# ipro6s register map
Vendor: intelpro; Series: IPRO6S
CPU: ipro6s, little endian
Registers are 32-bit, read-write, reset 0x0 unless marked. A register's access mark holds for its fields unless they carry their own. Offsets are from the block's base; [hi:lo] are bit positions; {n}, {i} and the like mark numbered series.

## RF (part 2 of 2)
Base 0x30001000
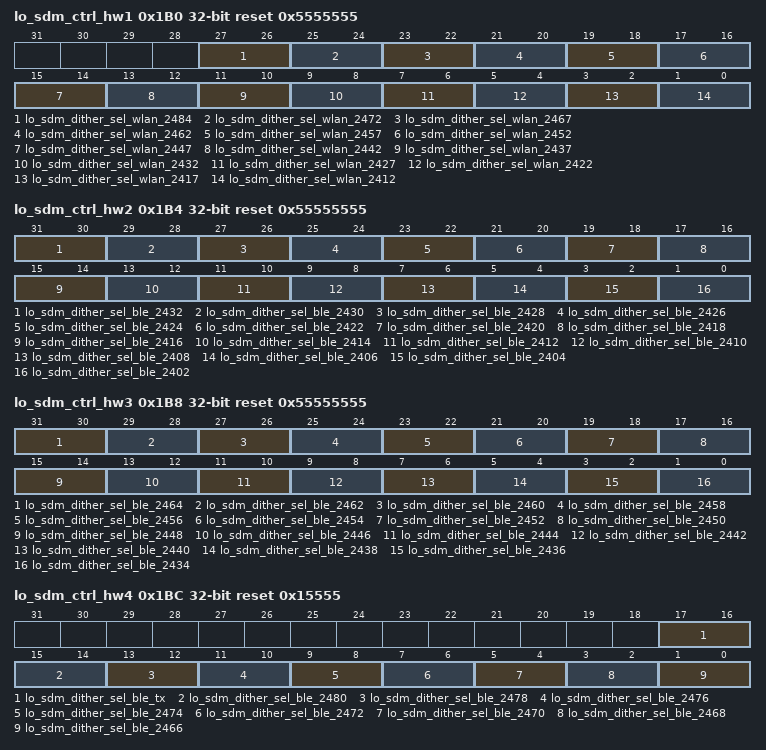
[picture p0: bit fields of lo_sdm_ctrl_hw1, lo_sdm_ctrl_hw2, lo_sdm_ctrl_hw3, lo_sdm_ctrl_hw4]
0x1B0 lo_sdm_ctrl_hw1 reset 0x5555555
  [27:26] lo_sdm_dither_sel_wlan_2484, [25:24] lo_sdm_dither_sel_wlan_2472, [23:22] lo_sdm_dither_sel_wlan_2467, [21:20] lo_sdm_dither_sel_wlan_2462, [19:18] lo_sdm_dither_sel_wlan_2457, [17:16] lo_sdm_dither_sel_wlan_2452, [15:14] lo_sdm_dither_sel_wlan_2447, [13:12] lo_sdm_dither_sel_wlan_2442, [11:10] lo_sdm_dither_sel_wlan_2437, [9:8] lo_sdm_dither_sel_wlan_2432, [7:6] lo_sdm_dither_sel_wlan_2427, [5:4] lo_sdm_dither_sel_wlan_2422, [3:2] lo_sdm_dither_sel_wlan_2417, [1:0] lo_sdm_dither_sel_wlan_2412
0x1B4 lo_sdm_ctrl_hw2 reset 0x55555555
  [31:30] lo_sdm_dither_sel_ble_2432, [29:28] lo_sdm_dither_sel_ble_2430, [27:26] lo_sdm_dither_sel_ble_2428, [25:24] lo_sdm_dither_sel_ble_2426, [23:22] lo_sdm_dither_sel_ble_2424, [21:20] lo_sdm_dither_sel_ble_2422, [19:18] lo_sdm_dither_sel_ble_2420, [17:16] lo_sdm_dither_sel_ble_2418, [15:14] lo_sdm_dither_sel_ble_2416, [13:12] lo_sdm_dither_sel_ble_2414, [11:10] lo_sdm_dither_sel_ble_2412, [9:8] lo_sdm_dither_sel_ble_2410, [7:6] lo_sdm_dither_sel_ble_2408, [5:4] lo_sdm_dither_sel_ble_2406, [3:2] lo_sdm_dither_sel_ble_2404, [1:0] lo_sdm_dither_sel_ble_2402
0x1B8 lo_sdm_ctrl_hw3 reset 0x55555555
  [31:30] lo_sdm_dither_sel_ble_2464, [29:28] lo_sdm_dither_sel_ble_2462, [27:26] lo_sdm_dither_sel_ble_2460, [25:24] lo_sdm_dither_sel_ble_2458, [23:22] lo_sdm_dither_sel_ble_2456, [21:20] lo_sdm_dither_sel_ble_2454, [19:18] lo_sdm_dither_sel_ble_2452, [17:16] lo_sdm_dither_sel_ble_2450, [15:14] lo_sdm_dither_sel_ble_2448, [13:12] lo_sdm_dither_sel_ble_2446, [11:10] lo_sdm_dither_sel_ble_2444, [9:8] lo_sdm_dither_sel_ble_2442, [7:6] lo_sdm_dither_sel_ble_2440, [5:4] lo_sdm_dither_sel_ble_2438, [3:2] lo_sdm_dither_sel_ble_2436, [1:0] lo_sdm_dither_sel_ble_2434
0x1BC lo_sdm_ctrl_hw4 reset 0x15555
  [17:16] lo_sdm_dither_sel_ble_tx, [15:14] lo_sdm_dither_sel_ble_2480, [13:12] lo_sdm_dither_sel_ble_2478, [11:10] lo_sdm_dither_sel_ble_2476, [9:8] lo_sdm_dither_sel_ble_2474, [7:6] lo_sdm_dither_sel_ble_2472, [5:4] lo_sdm_dither_sel_ble_2470, [3:2] lo_sdm_dither_sel_ble_2468, [1:0] lo_sdm_dither_sel_ble_2466
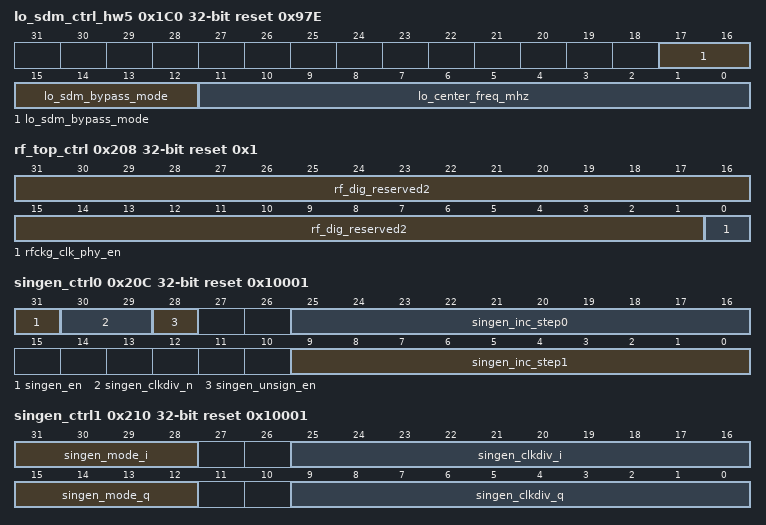
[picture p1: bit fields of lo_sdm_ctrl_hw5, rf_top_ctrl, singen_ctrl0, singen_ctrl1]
0x1C0 lo_sdm_ctrl_hw5 reset 0x97E
  [17:12] lo_sdm_bypass_mode, [11:0] lo_center_freq_mhz
0x1C4 lo_sdm_ctrl_hw6 reset 0x14400000
  [28:0] lo_sdmin_center
0x1C8 lo_sdm_ctrl_hw7 reset 0x22222
  [19:0] lo_sdmin_1m
0x1CC lo_sdm_ctrl_hw8 reset 0x2AAAB
  [19:0] lo_sdmin_if
0x1D0 rbb_bw_ctrl_hw reset 0x1
  [0] rbb_bt_mode_ble
0x208 rf_top_ctrl reset 0x1
  [31:1] rf_dig_reserved2 — reserved register for rf_top digital part
  [0] rfckg_clk_phy_en — 1:enable phy clock
0x20C singen_ctrl0 reset 0x10001
  [31] singen_en — 1: singen enable
  [30:29] singen_clkdiv_n — div by 1024^n
  [28] singen_unsign_en — 0:signed output 1:unsigned output
  [25:16] singen_inc_step0 — 1st tone step
  [9:0] singen_inc_step1 — 2nd tone step
0x210 singen_ctrl1 reset 0x10001
  [31:28] singen_mode_i — 0: single-tone, 1: two-tone, 2: ramp_up, 3: ramp_down, 4: LFSR24, 5: LFSR16, 6: LFSR12, 7: LFSR8
  [25:16] singen_clkdiv_i — 1x~1/1024x, default 10'd1
  [15:12] singen_mode_q — 0: single-tone, 1: two-tone, 2: ramp_up, 3: ramp_down, 4: LFSR24, 5: LFSR16, 6: LFSR12, 7: LFSR8
  [9:0] singen_clkdiv_q — 1x~1/1024x, default 10'd1
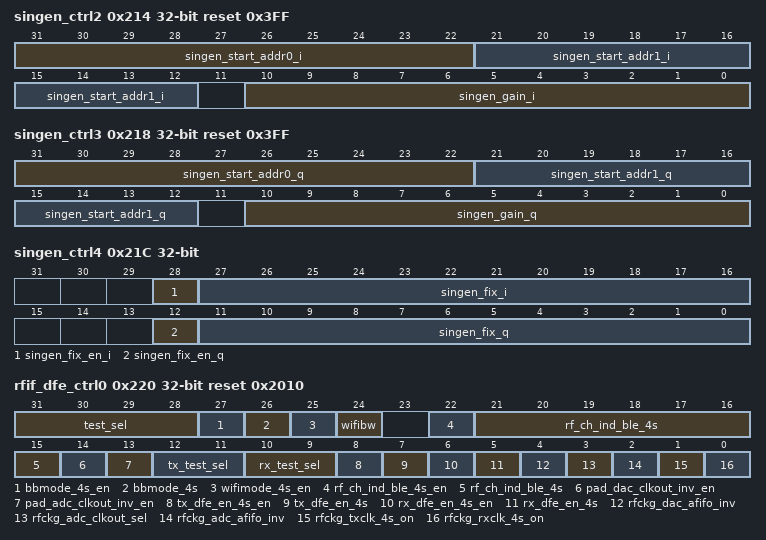
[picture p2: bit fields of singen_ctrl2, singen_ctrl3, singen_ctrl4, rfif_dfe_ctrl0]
0x214 singen_ctrl2 reset 0x3FF
  [31:22] singen_start_addr0_i — singen table start address 0
  [21:12] singen_start_addr1_i — singen table start address 1
  [10:0] singen_gain_i — 2x~1/1024x, default 11'd1023
0x218 singen_ctrl3 reset 0x3FF
  [31:22] singen_start_addr0_q — singen table start address 0
  [21:12] singen_start_addr1_q — singen table start address 1
  [10:0] singen_gain_q — 2x~1/1024x, default 11'd1023
0x21C singen_ctrl4
  [28] singen_fix_en_i — 1: enable fix value
  [27:16] singen_fix_i — output constant value
  [12] singen_fix_en_q — 1: enable fix value
  [11:0] singen_fix_q — output constant value
0x220 rfif_dfe_ctrl0 reset 0x2010
  [31:28] test_sel — 4'd0:disable 4'd1:pkdet_out, adc_rxhbf_out 4'd2:pkdet_out, rf_adc_dout 4'd3:dac_in_mux 4'd4:rf_dac_din 4'd5:dac_fifo_status 4'd6:adc_fifo_status 4'd7:agc_ctrl, pkdet_out, clocks
  [27] bbmode_4s_en — 0:from mac, 1:from reg
  [26] bbmode_4s — 0:wifi, 1:ble
  [25] wifimode_4s_en — 0:from mac, 1:from reg
  [24] wifibw — 0:BW20(40MHz), 1:BW40(80MHz)
  [22] rf_ch_ind_ble_4s_en — 0:from mac, 1:from reg
  [21:15] rf_ch_ind_ble_4s — channel index
  [14] pad_dac_clkout_inv_en — 1 :invert clock
  [13] pad_adc_clkout_inv_en — 1: invert clock
  [12:11] tx_test_sel — 0:nomal mode, 1:test from sram, 2:test from singen, 3:test from pad
  [10:9] rx_test_sel — 0:ADC 80m, 1:wifi 40m, 2:ble 16m, 3:reserved
  [8] tx_dfe_en_4s_en — 0:from mac, 1:from reg
  [7] tx_dfe_en_4s — 1:enable
  [6] rx_dfe_en_4s_en — 0:from mac, 1:from reg
  [5] rx_dfe_en_4s — 1:enable
  [4] rfckg_dac_afifo_inv — 1: invert clock
  [3] rfckg_adc_clkout_sel — 0: select clk_adc_clkout_i, 1:select clk_adc_clkout_q
  [2] rfckg_adc_afifo_inv — 1: invert clock
  [1] rfckg_txclk_4s_on — 1:force clock on without clock gating
  [0] rfckg_rxclk_4s_on — 1:force clock on without clock gating
0x224 rfif_test_read reset not defined
  [31:0] test_read ro — rfif_test_read is selected by rfif_test_sel[3:0] 4'd1:{rxclk_sel_dbg, 2'b0, pkdet_out_dbg, adc_rxhbf_out_i[11:0], rxclk_sel_dbg, 2'b0, pkdet_out_dbg, adc_rxhbf_out_q[11:0]} 4'd2:{rxclk_sel_dbg, 4'b0, pkdet_out_dbg, rf_adc_dout_i[9:0], rxclk_sel_dbg, 4'b0, pkdet_out_dbg, rf_adc_dout_q[9:0]} 4'd3:{txclk_sin_dbg, 1'b0, DACEn0, dac_tx_sin_dout_tg, dac_in_mux_i[11:0], txclk_sin_dbg, 1'b0, DACEn0, dac_tx_sin_dout_tg, dac_in_mux_q[11:0]} 4'd4:{txclk_sin_dbg, 2'b0, DACEn0, dac_tx_sin_dout_tg, rf_dac_din_i[10:0], txclk_sin_dbg, 2'b0, DACEn0, dac_tx_sin_dout_tg, rf_dac_din_q[10:0]} 4'd5:dac_afifo_status 4'd6:adc_afifo_status 4'd7:{5'b0, agc_ctrl_from_pad[9:0], pkdet_out_to_pad, 2'b0, fclk_sdm_dbg, clk_clkip_soc_1m_dbg, clk_clkip_soc_2m_dbg, clk_clkip_soc_10m_dbg, clk_clkip_soc_20m_dbg, clk_clkip_soc_40m_dbg, clk_clkip_soc_60m_dbg, clk_clkip_soc_120m_dbg, clk_clkip_soc_160m_dbg, clk_clkip_soc_240m_dbg, clk_clkip_test_480m_dbg, clk_refbuf_soc_38p4m_dbg, clkpll_out_dbg, pkdet_out_dbg} Note for agc_ctrl_from_pad[9:0] pkdet_out_rstn = agc_ctrl_from_pad[9], reset pkdet (low active) gc_rbb2_hw = agc_ctrl_from_pad[8:6] gc_rbb1_hw = agc_ctrl_from_pad[5:4] gc_rmxgm_hw = agc_ctrl_from_pad[3] gc_lna_hw = agc_ctrl_from_pad[2:0]
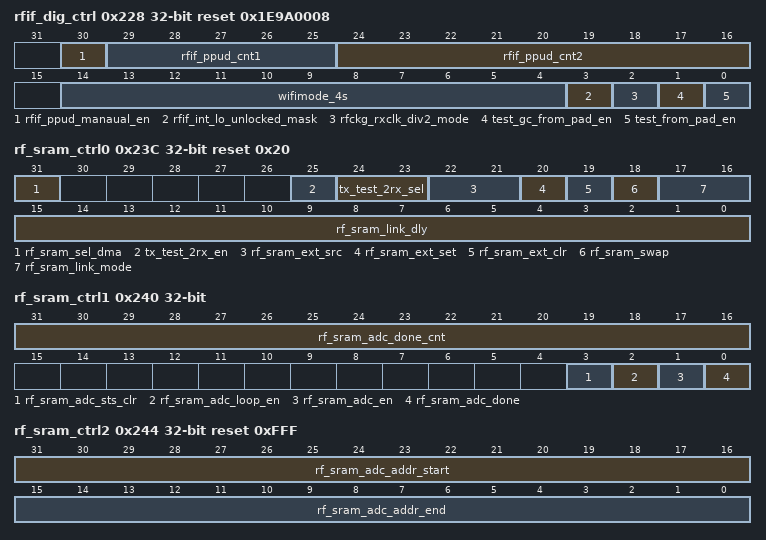
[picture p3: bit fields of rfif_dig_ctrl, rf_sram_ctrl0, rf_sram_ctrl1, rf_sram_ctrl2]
0x228 rfif_dig_ctrl reset 0x1E9A0008
  [30] rfif_ppud_manaual_en — 1:enable pu/ppud/ppud manaual mode
  [29:25] rfif_ppud_cnt1 — counter value of ppu
  [24:16] rfif_ppud_cnt2 — counter value of pud
  [14:4] wifimode_4s — formatMod[3:0],legRate[3:0],mcs[2:0]
  [3] rfif_int_lo_unlocked_mask — 0:unmask interrupt 1:mask interrupt
  [2] rfckg_rxclk_div2_mode
  [1] test_gc_from_pad_en — 0:normal signals from FSM 1:test RX gain control from PAD
  [0] test_from_pad_en — 0:normal signals from RIU 1:test ADC/DAC/AGC from PAD
{0x22C+4i} rf_data_temp_{i} (i=0..3)
  [31:0] rf_data_temp_{i} — register for temporary data buffer
0x23C rf_sram_ctrl0 reset 0x20
  [31] rf_sram_sel_dma — 1:select dma mode
  [25] tx_test_2rx_en — 1:enable tx 2 rx mixed path
  [24:23] tx_test_2rx_sel — 0:80m dpd in, 1:80m dpd out, 2:40m dpd in, 3:40m dpd out
  [22:21] rf_sram_ext_src — 0:fsm_txdfe_en, 1:fsm_rxdfe_en, 2:rf_detrampup, 3:reserved
  [20] rf_sram_ext_set — 1:force external trigger
  [19] rf_sram_ext_clr — 1:clear external trigger level DFF
  [18] rf_sram_swap — 1'b0:adc->sram0, sram1->dac 1'b1:sram0->dac, adc->sram1
  [17:16] rf_sram_link_mode — 2'b00:adc/dac independent 2'b01:trigger adc->delay->dac 2'b10:trigger dac->delay->adc 2'b11:trigger by externl source
  [15:0] rf_sram_link_dly — link delay cycle
0x240 rf_sram_ctrl1 (reset mask 0xE)
  [31:16] rf_sram_adc_done_cnt ro
  [3] rf_sram_adc_sts_clr — 1:clear adc fifo status
  [2] rf_sram_adc_loop_en — 1:loop enable
  [1] rf_sram_adc_en — 1:enable adc sram record
  [0] rf_sram_adc_done ro — 1:done
0x244 rf_sram_ctrl2 reset 0xFFF
  [31:16] rf_sram_adc_addr_start — start address(4-byte address)
  [15:0] rf_sram_adc_addr_end — end address(4-byte address)
0x248 rf_sram_ctrl3 reset not defined
  [31:0] rf_sram_adc_sts ro — async fifo status
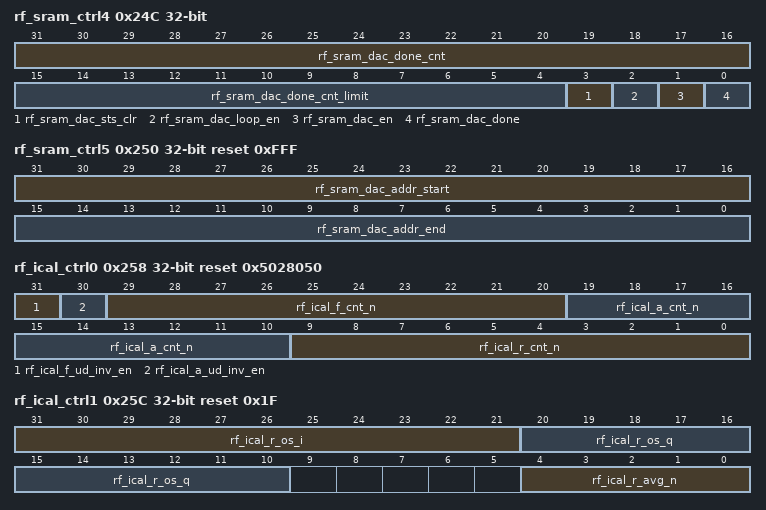
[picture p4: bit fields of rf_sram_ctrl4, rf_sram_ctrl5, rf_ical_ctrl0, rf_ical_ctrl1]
0x24C rf_sram_ctrl4 (reset mask 0xFFFE)
  [31:16] rf_sram_dac_done_cnt ro
  [15:4] rf_sram_dac_done_cnt_limit
  [3] rf_sram_dac_sts_clr — 1:clear dac fifo status
  [2] rf_sram_dac_loop_en — 1:loop enable
  [1] rf_sram_dac_en — 1:enable dac sram record
  [0] rf_sram_dac_done ro — 1:done
0x250 rf_sram_ctrl5 reset 0xFFF
  [31:16] rf_sram_dac_addr_start — start address(4-byte address)
  [15:0] rf_sram_dac_addr_end — end address(4-byte address)
0x254 rf_sram_ctrl6 reset not defined
  [31:0] rf_sram_dac_sts ro — async fifo status
0x258 rf_ical_ctrl0 reset 0x5028050
  [31] rf_ical_f_ud_inv_en, [30] rf_ical_a_ud_inv_en, [29:20] rf_ical_f_cnt_n, [19:10] rf_ical_a_cnt_n, [9:0] rf_ical_r_cnt_n
0x25C rf_ical_ctrl1 reset 0x1F (reset mask 0x1F)
  [31:21] rf_ical_r_os_i ro, [20:10] rf_ical_r_os_q ro, [4:0] rf_ical_r_avg_n
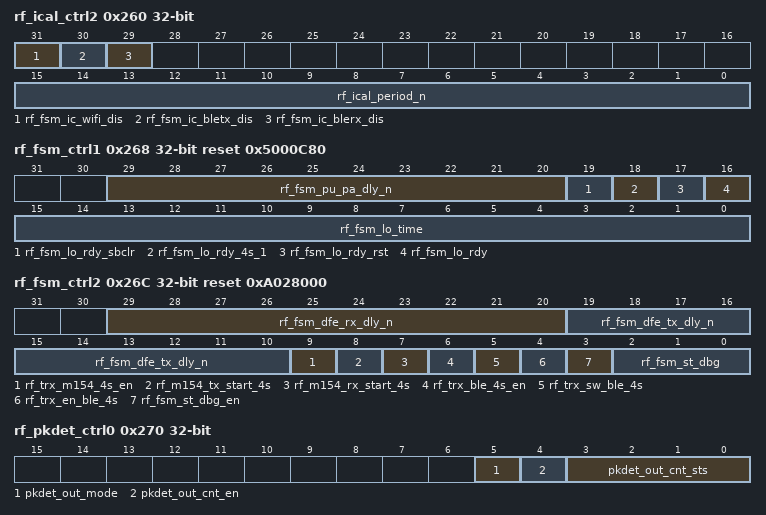
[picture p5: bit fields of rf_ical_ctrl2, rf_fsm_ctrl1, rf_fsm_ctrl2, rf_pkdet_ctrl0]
0x260 rf_ical_ctrl2
  [31] rf_fsm_ic_wifi_dis
  [30] rf_fsm_ic_bletx_dis
  [29] rf_fsm_ic_blerx_dis
  [15:0] rf_ical_period_n — incremental calibration period
0x264 rf_fsm_ctrl0 reset 0x99C
  [11:0] rf_ch_ind_wifi
0x268 rf_fsm_ctrl1 reset 0x5000C80 (reset mask 0x3FFEFFFF)
  [29:20] rf_fsm_pu_pa_dly_n, [19] rf_fsm_lo_rdy_sbclr, [18] rf_fsm_lo_rdy_4s_1, [17] rf_fsm_lo_rdy_rst, [16] rf_fsm_lo_rdy ro, [15:0] rf_fsm_lo_time
0x26C rf_fsm_ctrl2 reset 0xA028000
  [29:20] rf_fsm_dfe_rx_dly_n
  [19:10] rf_fsm_dfe_tx_dly_n
  [9] rf_trx_m154_4s_en
  [8] rf_m154_tx_start_4s
  [7] rf_m154_rx_start_4s
  [6] rf_trx_ble_4s_en
  [5] rf_trx_sw_ble_4s
  [4] rf_trx_en_ble_4s
  [3] rf_fsm_st_dbg_en — 1:enable RF state from SW
  [2:0] rf_fsm_st_dbg — SW RF state value
0x270 rf_pkdet_ctrl0 (reset mask 0x30)
  [5] pkdet_out_mode — 0:ana latch pkdet 1:dig latch pkdet
  [4] pkdet_out_cnt_en
  [3:0] pkdet_out_cnt_sts ro
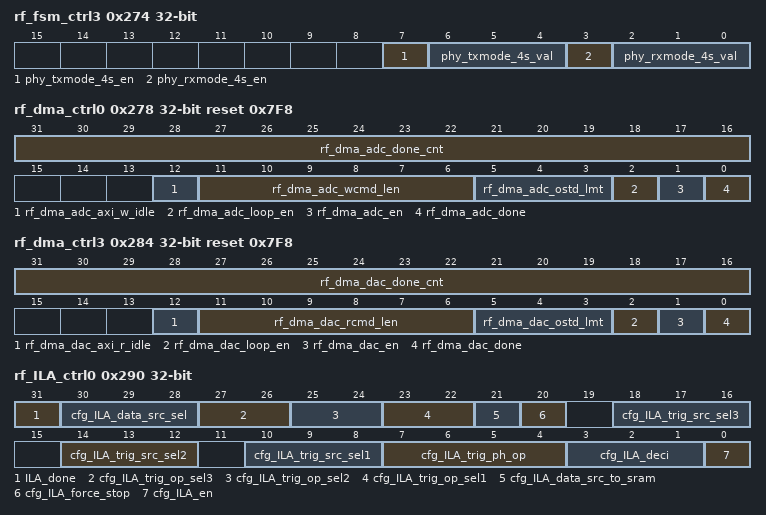
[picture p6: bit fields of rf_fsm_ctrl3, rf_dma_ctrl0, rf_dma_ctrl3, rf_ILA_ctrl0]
0x274 rf_fsm_ctrl3
  [7] phy_txmode_4s_en, [6:4] phy_txmode_4s_val, [3] phy_rxmode_4s_en, [2:0] phy_rxmode_4s_val
0x278 rf_dma_ctrl0 reset 0x7F8 (reset mask 0xFFE)
  [31:16] rf_dma_adc_done_cnt ro
  [12] rf_dma_adc_axi_w_idle ro — 1:axi idle
  [11:6] rf_dma_adc_wcmd_len
  [5:3] rf_dma_adc_ostd_lmt
  [2] rf_dma_adc_loop_en — 1:loop enable
  [1] rf_dma_adc_en — 1:enable adc dma record
  [0] rf_dma_adc_done ro — 1:done
0x27C rf_dma_ctrl1 reset 0x50000100
  [31:0] rf_dma_adc_addr_start — start address(byte address)
0x280 rf_dma_ctrl2 reset 0xF00
  [31:0] rf_dma_adc_addr_cnt — number of 32-bit words to be sent
0x284 rf_dma_ctrl3 reset 0x7F8 (reset mask 0xFFE)
  [31:16] rf_dma_dac_done_cnt ro
  [12] rf_dma_dac_axi_r_idle ro — 1:axi idle
  [11:6] rf_dma_dac_rcmd_len
  [5:3] rf_dma_dac_ostd_lmt
  [2] rf_dma_dac_loop_en — 1:loop enable
  [1] rf_dma_dac_en — 1:enable adc dma record
  [0] rf_dma_dac_done ro — 1:done
0x288 rf_dma_ctrl5 reset 0x50000100
  [31:0] rf_dma_dac_addr_start — start address(byte address)
0x28C rf_dma_ctrl6 reset 0xF00
  [31:0] rf_dma_dac_addr_cnt — number of 32-bit words to be sent
0x290 rf_ILA_ctrl0 (reset mask 0x7FF777FF)
  [31] ILA_done ro, [30:28] cfg_ILA_data_src_sel, [27:26] cfg_ILA_trig_op_sel3, [25:24] cfg_ILA_trig_op_sel2, [23:22] cfg_ILA_trig_op_sel1, [21] cfg_ILA_data_src_to_sram, [20] cfg_ILA_force_stop wo, [18:16] cfg_ILA_trig_src_sel3, [14:12] cfg_ILA_trig_src_sel2, [10:8] cfg_ILA_trig_src_sel1, [7:4] cfg_ILA_trig_ph_op, [3:1] cfg_ILA_deci, [0] cfg_ILA_en
{0x290+4i} rf_ILA_ctrl{i} (i=1..3)
  [31:0] cfg_ILA_trig_mask_sel{i}
{0x290+4i} rf_ILA_ctrl{i} (i=4..6)
  [31:0] cfg_ILA_trig_target_sel{i-3}
0x2AC rf_ILA_ctrl7
  [31:0] cfg_ILA_end_cnt
0x2B0 rf_ILA_ctrl8 reset not defined
  [15:0] rf_sram_adc_addr_keep ro
0x2B4 rf_ILA_ctrl9 reset not defined
  [31:0] rf_dma_adc_addr_keep ro
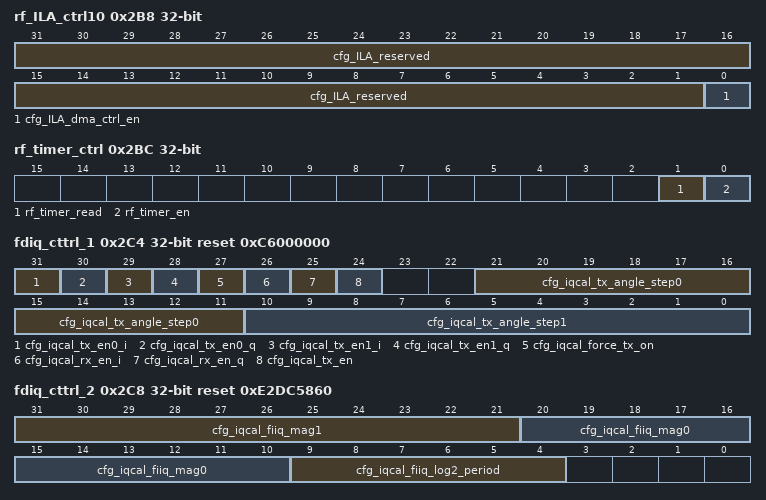
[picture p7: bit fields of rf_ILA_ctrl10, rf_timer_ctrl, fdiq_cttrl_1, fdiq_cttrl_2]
0x2B8 rf_ILA_ctrl10
  [31:1] cfg_ILA_reserved, [0] cfg_ILA_dma_ctrl_en
0x2BC rf_timer_ctrl
  [1] rf_timer_read, [0] rf_timer_en
0x2C0 rf_timer_value reset not defined
  [31:0] rf_timer_keep ro
0x2C4 fdiq_cttrl_1 reset 0xC6000000
  [31] cfg_iqcal_tx_en0_i — Calibration Tone gen0 en
  [30] cfg_iqcal_tx_en0_q — Calibration Tone gen0 en
  [29] cfg_iqcal_tx_en1_i — Calibration Tone gen1 en
  [28] cfg_iqcal_tx_en1_q — Calibration Tone gen1 en
  [27] cfg_iqcal_force_tx_on — Calibratoin force tx on
  [26] cfg_iqcal_rx_en_i — Calibration Tx0
  [25] cfg_iqcal_rx_en_q — Calibration Tx1
  [24] cfg_iqcal_tx_en — Calibration Tx1
  [21:11] cfg_iqcal_tx_angle_step0 — tx_angle_step0
  [10:0] cfg_iqcal_tx_angle_step1 — tx_angle_step1
0x2C8 fdiq_cttrl_2 reset 0xE2DC5860
  [31:21] cfg_iqcal_fiiq_mag1 — FIIQ CAL Mag1
  [20:10] cfg_iqcal_fiiq_mag0 — FIIQ CAL Mag
  [9:4] cfg_iqcal_fiiq_log2_period — FIIQ Log2(Number of period)
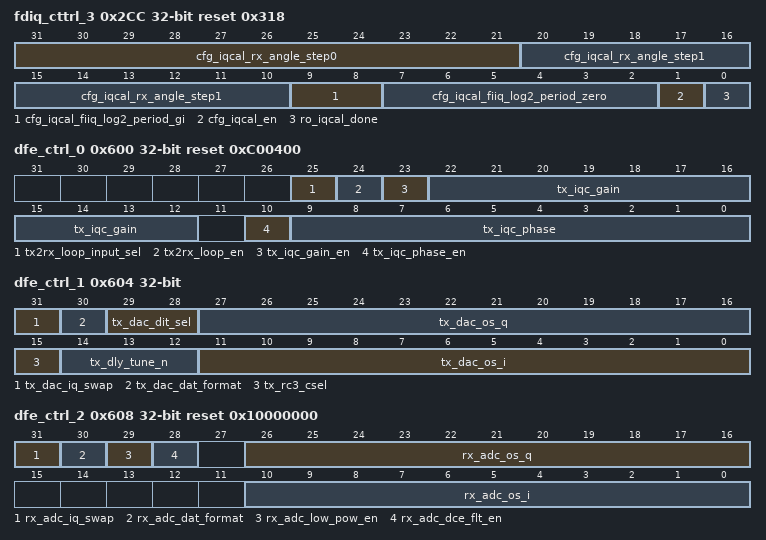
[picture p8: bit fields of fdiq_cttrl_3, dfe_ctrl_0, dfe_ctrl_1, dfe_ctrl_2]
0x2CC fdiq_cttrl_3 reset 0x318 (reset mask 0xFFFFFFFE)
  [31:21] cfg_iqcal_rx_angle_step0 — rx_angle_step0
  [20:10] cfg_iqcal_rx_angle_step1 — rx_angle_step1
  [9:8] cfg_iqcal_fiiq_log2_period_gi — FIIQ Log2(Number of period GI)
  [7:2] cfg_iqcal_fiiq_log2_period_zero — FIIQ Log2(Number of period zero)
  [1] cfg_iqcal_en — calibration enable
  [0] ro_iqcal_done ro — IQ cal done
0x2D0 iq_cal_rxtone_result0 reset not defined
  [27:0] ro_dc_acc_i ro — dc acculation out I
0x2D4 iq_cal_rxtone_result1 reset not defined
  [27:0] ro_dc_acc_q ro — dc acculation out q
0x2D8 iq_cal_rxtone_result2 reset not defined
  [27:0] ro_pos_acc_i_freq0 ro — pos 0 freq result
0x2DC iq_cal_rxtone_result3 reset not defined
  [27:0] ro_pos_acc_q_freq0 ro — pos 0 freq result
0x2E0 iq_cal_rxtone_result4 reset not defined
  [27:0] ro_neg_acc_i_freq0 ro — neg 0 freq result
0x2E4 iq_cal_rxtone_result5 reset not defined
  [27:0] ro_neg_acc_q_freq0 ro — neg 0 freq result
0x2E8 iq_cal_rxtone_result6 reset not defined
  [27:0] ro_pos_acc_i_freq1 ro — pos 1 freq result
0x2EC iq_cal_rxtone_result7 reset not defined
  [27:0] ro_pos_acc_q_freq1 ro — pos 1 freq result
0x2F0 iq_cal_rxtone_result8 reset not defined
  [27:0] ro_neg_acc_i_freq1 ro — neg 1 freq result
0x2F4 iq_cal_rxtone_result9 reset not defined
  [27:0] ro_neg_acc_q_freq1 ro — neg 1 freq result
0x2F8 iq_cal_rxtone_result10 reset not defined
  [31:0] ro_power_acc_i ro — power acc i
0x2FC iq_cal_rxtone_result11 reset not defined
  [31:0] ro_power_acc_q ro — power acc q
0x600 dfe_ctrl_0 reset 0xC00400
  [25] tx2rx_loop_input_sel, [24] tx2rx_loop_en, [23] tx_iqc_gain_en, [22:12] tx_iqc_gain, [10] tx_iqc_phase_en, [9:0] tx_iqc_phase
0x604 dfe_ctrl_1
  [31] tx_dac_iq_swap, [30] tx_dac_dat_format, [29:28] tx_dac_dit_sel, [27:16] tx_dac_os_q, [15] tx_rc3_csel, [14:12] tx_dly_tune_n, [11:0] tx_dac_os_i
0x608 dfe_ctrl_2 reset 0x10000000
  [31] rx_adc_iq_swap, [30] rx_adc_dat_format, [29] rx_adc_low_pow_en, [28] rx_adc_dce_flt_en, [26:16] rx_adc_os_q, [10:0] rx_adc_os_i
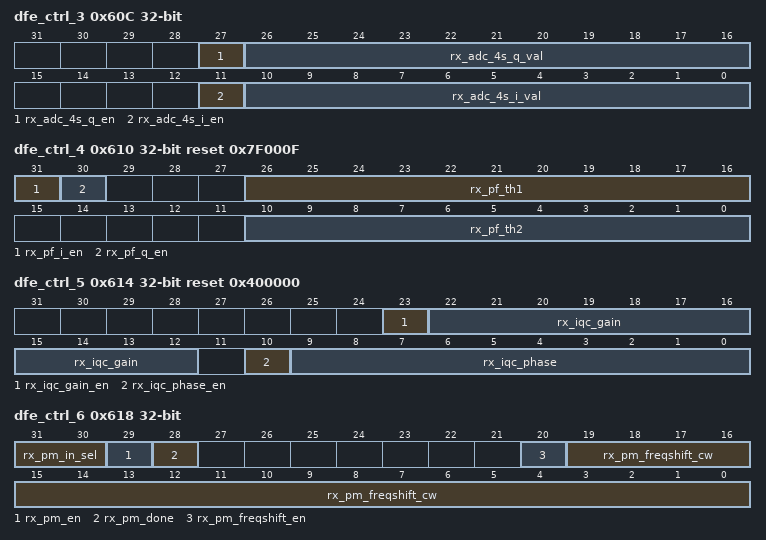
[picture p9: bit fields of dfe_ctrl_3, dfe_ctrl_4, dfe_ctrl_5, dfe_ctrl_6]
0x60C dfe_ctrl_3
  [27] rx_adc_4s_q_en, [26:16] rx_adc_4s_q_val, [11] rx_adc_4s_i_en, [10:0] rx_adc_4s_i_val
0x610 dfe_ctrl_4 reset 0x7F000F
  [31] rx_pf_i_en, [30] rx_pf_q_en, [26:16] rx_pf_th1, [10:0] rx_pf_th2
0x614 dfe_ctrl_5 reset 0x400000
  [23] rx_iqc_gain_en, [22:12] rx_iqc_gain, [10] rx_iqc_phase_en, [9:0] rx_iqc_phase
0x618 dfe_ctrl_6 (reset mask 0xE01FFFFF)
  [31:30] rx_pm_in_sel, [29] rx_pm_en, [28] rx_pm_done ro, [20] rx_pm_freqshift_en, [19:0] rx_pm_freqshift_cw
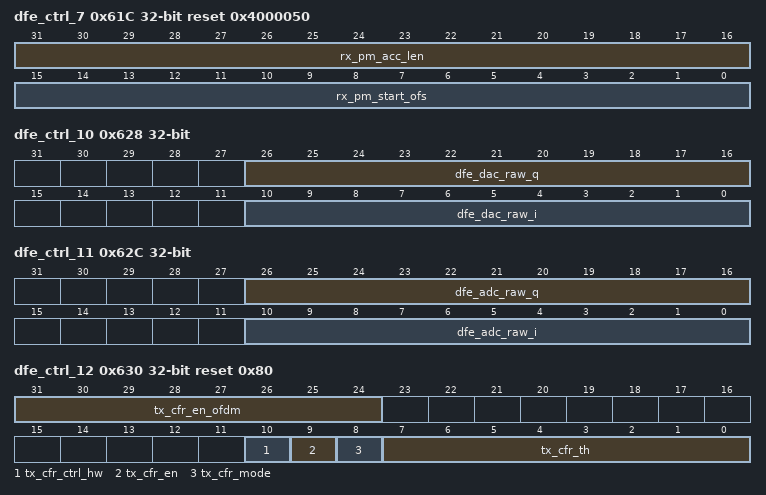
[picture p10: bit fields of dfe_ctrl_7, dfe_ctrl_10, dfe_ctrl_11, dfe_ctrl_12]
0x61C dfe_ctrl_7 reset 0x4000050
  [31:16] rx_pm_acc_len, [15:0] rx_pm_start_ofs
0x620 dfe_ctrl_8 reset not defined
  [24:0] rx_pm_iqacc_i ro
0x624 dfe_ctrl_9 reset not defined
  [24:0] rx_pm_iqacc_q ro
0x628 dfe_ctrl_10 reset not defined
  [26:16] dfe_dac_raw_q ro, [10:0] dfe_dac_raw_i ro
0x62C dfe_ctrl_11 reset not defined
  [26:16] dfe_adc_raw_q ro, [10:0] dfe_adc_raw_i ro
0x630 dfe_ctrl_12 reset 0x80
  [31:24] tx_cfr_en_ofdm, [10] tx_cfr_ctrl_hw, [9] tx_cfr_en, [8] tx_cfr_mode, [7:0] tx_cfr_th
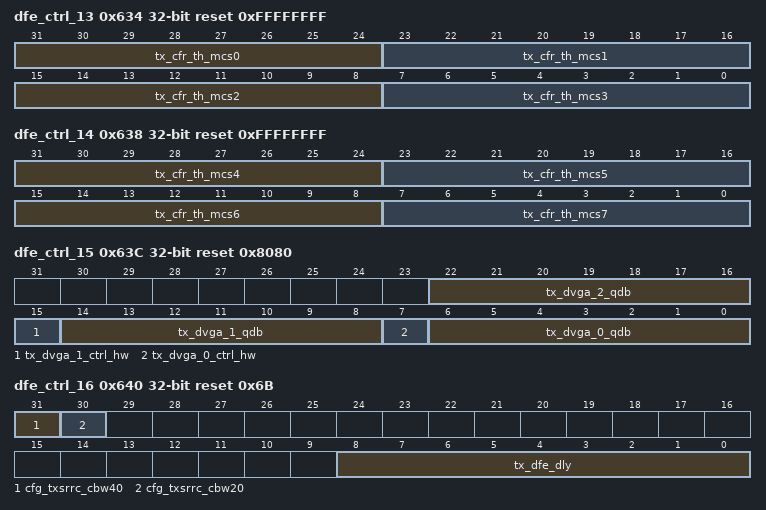
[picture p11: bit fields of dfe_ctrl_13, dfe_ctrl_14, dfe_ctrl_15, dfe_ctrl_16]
0x634 dfe_ctrl_13 reset 0xFFFFFFFF
  [31-8n:24-8n] tx_cfr_th_mcs{n} (n=0..3)
0x638 dfe_ctrl_14 reset 0xFFFFFFFF
  [63-8n:56-8n] tx_cfr_th_mcs{n} (n=4..7)
0x63C dfe_ctrl_15 reset 0x8080
  [22:16] tx_dvga_2_qdb, [15] tx_dvga_1_ctrl_hw, [14:8] tx_dvga_1_qdb, [7] tx_dvga_0_ctrl_hw, [6:0] tx_dvga_0_qdb
0x640 dfe_ctrl_16 reset 0x6B
  [31] cfg_txsrrc_cbw40, [30] cfg_txsrrc_cbw20, [8:0] tx_dfe_dly
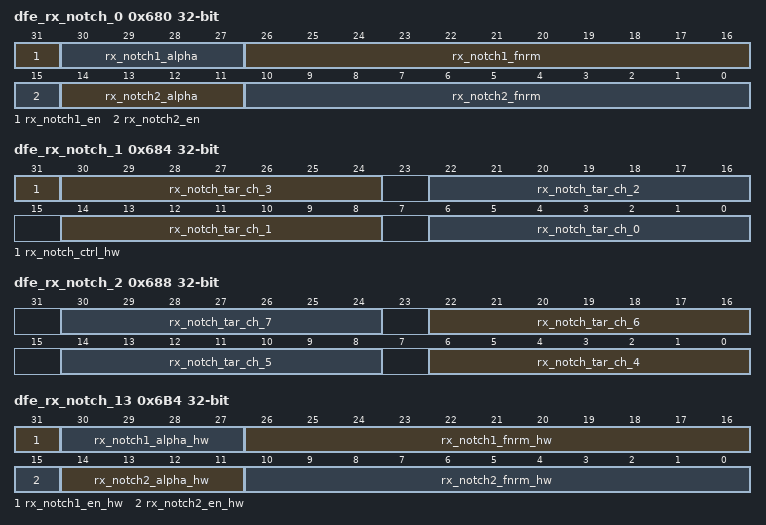
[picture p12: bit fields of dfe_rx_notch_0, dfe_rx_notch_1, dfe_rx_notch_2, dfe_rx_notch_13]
0x680 dfe_rx_notch_0
  [31] rx_notch1_en, [30:27] rx_notch1_alpha, [26:16] rx_notch1_fnrm, [15] rx_notch2_en, [14:11] rx_notch2_alpha, [10:0] rx_notch2_fnrm
0x684 dfe_rx_notch_1
  [31] rx_notch_ctrl_hw, [8n+6:8n] rx_notch_tar_ch_{n} (n=0..3)
0x688 dfe_rx_notch_2
  [8n-26:8n-32] rx_notch_tar_ch_{n} (n=4..7)
0x68C dfe_rx_notch_3
  [6:0] rx_notch_tar_ch_8
0x690 dfe_rx_notch_4
  [31:0] rx_notch_para_0 — [31] rx_notch1_en [30:27] rx_notch1_alpha [26:16] rx_notch1_fnrm [15] rx_notch2_en [14:11] rx_notch2_alpha [10:0] rx_notch2_fnrm
{0x680+4i} dfe_rx_notch_{i} (i=5..12)
  [31:0] rx_notch_para_{i-4}
0x6B4 dfe_rx_notch_13 reset not defined
  [31] rx_notch1_en_hw ro, [30:27] rx_notch1_alpha_hw ro, [26:16] rx_notch1_fnrm_hw ro, [15] rx_notch2_en_hw ro, [14:11] rx_notch2_alpha_hw ro, [10:0] rx_notch2_fnrm_hw ro
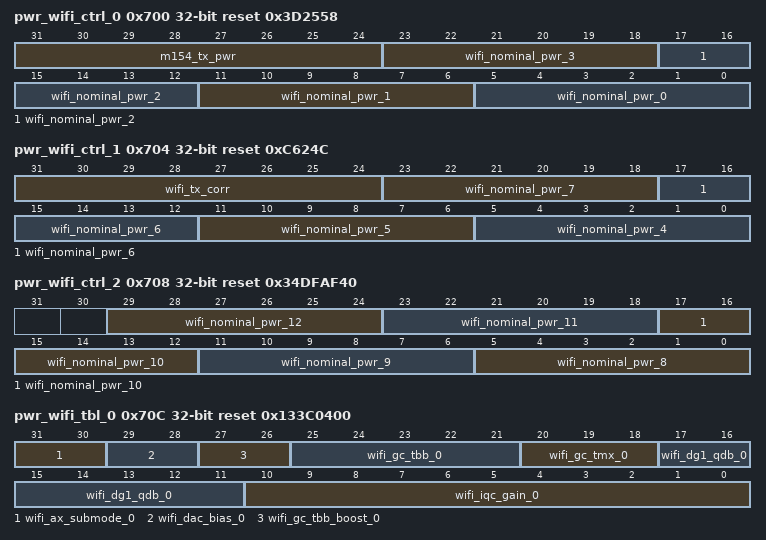
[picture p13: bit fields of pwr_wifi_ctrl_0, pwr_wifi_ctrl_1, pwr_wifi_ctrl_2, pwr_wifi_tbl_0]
0x700 pwr_wifi_ctrl_0 reset 0x3D2558
  [31:24] m154_tx_pwr, [6n+5:6n] wifi_nominal_pwr_{n} (n=0..3)
0x704 pwr_wifi_ctrl_1 reset 0xC624C
  [31:24] wifi_tx_corr, [6n-19:6n-24] wifi_nominal_pwr_{n} (n=4..7)
0x708 pwr_wifi_ctrl_2 reset 0x34DFAF40
  [6n-43:6n-48] wifi_nominal_pwr_{n} (n=8..12)
0x70C pwr_wifi_tbl_0 reset 0x133C0400
  [31:30] wifi_ax_submode_0, [29:28] wifi_dac_bias_0, [27:26] wifi_gc_tbb_boost_0, [25:21] wifi_gc_tbb_0, [20:18] wifi_gc_tmx_0, [17:11] wifi_dg1_qdb_0, [10:0] wifi_iqc_gain_0
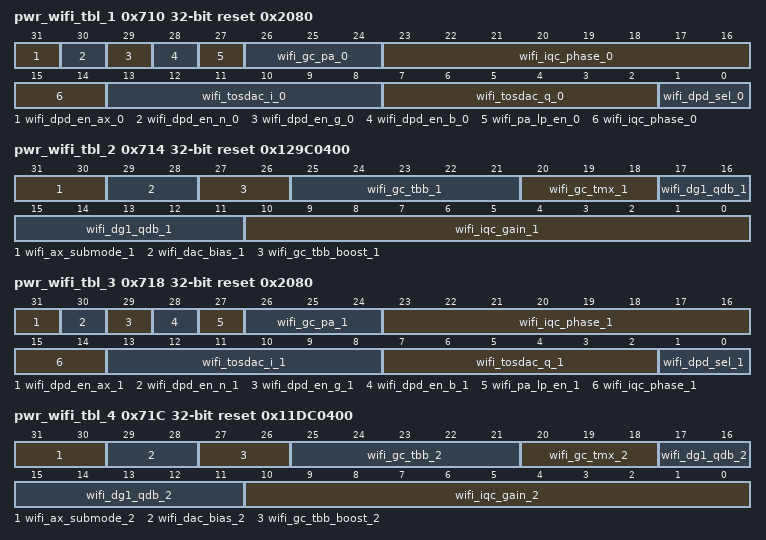
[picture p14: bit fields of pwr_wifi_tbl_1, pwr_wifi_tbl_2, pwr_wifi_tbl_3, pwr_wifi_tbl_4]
0x710 pwr_wifi_tbl_1 reset 0x2080
  [31] wifi_dpd_en_ax_0, [30] wifi_dpd_en_n_0, [29] wifi_dpd_en_g_0, [28] wifi_dpd_en_b_0, [27] wifi_pa_lp_en_0, [26:24] wifi_gc_pa_0, [23:14] wifi_iqc_phase_0, [13:8] wifi_tosdac_i_0, [7:2] wifi_tosdac_q_0, [1:0] wifi_dpd_sel_0
0x714 pwr_wifi_tbl_2 reset 0x129C0400
  [31:30] wifi_ax_submode_1, [29:28] wifi_dac_bias_1, [27:26] wifi_gc_tbb_boost_1, [25:21] wifi_gc_tbb_1, [20:18] wifi_gc_tmx_1, [17:11] wifi_dg1_qdb_1, [10:0] wifi_iqc_gain_1
0x718 pwr_wifi_tbl_3 reset 0x2080
  [31] wifi_dpd_en_ax_1, [30] wifi_dpd_en_n_1, [29] wifi_dpd_en_g_1, [28] wifi_dpd_en_b_1, [27] wifi_pa_lp_en_1, [26:24] wifi_gc_pa_1, [23:14] wifi_iqc_phase_1, [13:8] wifi_tosdac_i_1, [7:2] wifi_tosdac_q_1, [1:0] wifi_dpd_sel_1
0x71C pwr_wifi_tbl_4 reset 0x11DC0400
  [31:30] wifi_ax_submode_2, [29:28] wifi_dac_bias_2, [27:26] wifi_gc_tbb_boost_2, [25:21] wifi_gc_tbb_2, [20:18] wifi_gc_tmx_2, [17:11] wifi_dg1_qdb_2, [10:0] wifi_iqc_gain_2
0x720 pwr_wifi_tbl_5 reset 0x2080
  [31] wifi_dpd_en_ax_2, [30] wifi_dpd_en_n_2, [29] wifi_dpd_en_g_2, [28] wifi_dpd_en_b_2, [27] wifi_pa_lp_en_2, [26:24] wifi_gc_pa_2, [23:14] wifi_iqc_phase_2, [13:8] wifi_tosdac_i_2, [7:2] wifi_tosdac_q_2, [1:0] wifi_dpd_sel_2
0x724 pwr_wifi_tbl_6 reset 0x111FE400
  [31:30] wifi_ax_submode_3, [29:28] wifi_dac_bias_3, [27:26] wifi_gc_tbb_boost_3, [25:21] wifi_gc_tbb_3, [20:18] wifi_gc_tmx_3, [17:11] wifi_dg1_qdb_3, [10:0] wifi_iqc_gain_3
0x728 pwr_wifi_tbl_7 reset 0x2080
  [31] wifi_dpd_en_ax_3, [30] wifi_dpd_en_n_3, [29] wifi_dpd_en_g_3, [28] wifi_dpd_en_b_3, [27] wifi_pa_lp_en_3, [26:24] wifi_gc_pa_3, [23:14] wifi_iqc_phase_3, [13:8] wifi_tosdac_i_3, [7:2] wifi_tosdac_q_3, [1:0] wifi_dpd_sel_3
0x72C pwr_wifi_tbl_8 reset 0x10B82400
  [31:30] wifi_ax_submode_4, [29:28] wifi_dac_bias_4, [27:26] wifi_gc_tbb_boost_4, [25:21] wifi_gc_tbb_4, [20:18] wifi_gc_tmx_4, [17:11] wifi_dg1_qdb_4, [10:0] wifi_iqc_gain_4
0x730 pwr_wifi_tbl_9 reset 0x2080
  [31] wifi_dpd_en_ax_4, [30] wifi_dpd_en_n_4, [29] wifi_dpd_en_g_4, [28] wifi_dpd_en_b_4, [27] wifi_pa_lp_en_4, [26:24] wifi_gc_pa_4, [23:14] wifi_iqc_phase_4, [13:8] wifi_tosdac_i_4, [7:2] wifi_tosdac_q_4, [1:0] wifi_dpd_sel_4
0x734 pwr_wifi_tbl_10 reset 0x10978400
  [31:30] wifi_ax_submode_5, [29:28] wifi_dac_bias_5, [27:26] wifi_gc_tbb_boost_5, [25:21] wifi_gc_tbb_5, [20:18] wifi_gc_tmx_5, [17:11] wifi_dg1_qdb_5, [10:0] wifi_iqc_gain_5
0x738 pwr_wifi_tbl_11 reset 0x2080
  [31] wifi_dpd_en_ax_5, [30] wifi_dpd_en_n_5, [29] wifi_dpd_en_g_5, [28] wifi_dpd_en_b_5, [27] wifi_pa_lp_en_5, [26:24] wifi_gc_pa_5, [23:14] wifi_iqc_phase_5, [13:8] wifi_tosdac_i_5, [7:2] wifi_tosdac_q_5, [1:0] wifi_dpd_sel_5
0x73C pwr_wifi_tbl_12 reset 0x108C0400
  [31:30] wifi_ax_submode_6, [29:28] wifi_dac_bias_6, [27:26] wifi_gc_tbb_boost_6, [25:21] wifi_gc_tbb_6, [20:18] wifi_gc_tmx_6, [17:11] wifi_dg1_qdb_6, [10:0] wifi_iqc_gain_6
0x740 pwr_wifi_tbl_13 reset 0x2080
  [31] wifi_dpd_en_ax_6, [30] wifi_dpd_en_n_6, [29] wifi_dpd_en_g_6, [28] wifi_dpd_en_b_6, [27] wifi_pa_lp_en_6, [26:24] wifi_gc_pa_6, [23:14] wifi_iqc_phase_6, [13:8] wifi_tosdac_i_6, [7:2] wifi_tosdac_q_6, [1:0] wifi_dpd_sel_6
0x744 pwr_wifi_tbl_14 reset 0x10880400
  [31:30] wifi_ax_submode_7, [29:28] wifi_dac_bias_7, [27:26] wifi_gc_tbb_boost_7, [25:21] wifi_gc_tbb_7, [20:18] wifi_gc_tmx_7, [17:11] wifi_dg1_qdb_7, [10:0] wifi_iqc_gain_7
0x748 pwr_wifi_tbl_15 reset 0x2080
  [31] wifi_dpd_en_ax_7, [30] wifi_dpd_en_n_7, [29] wifi_dpd_en_g_7, [28] wifi_dpd_en_b_7, [27] wifi_pa_lp_en_7, [26:24] wifi_gc_pa_7, [23:14] wifi_iqc_phase_7, [13:8] wifi_tosdac_i_7, [7:2] wifi_tosdac_q_7, [1:0] wifi_dpd_sel_7
0x74C pwr_wifi_tbl_16 reset 0x10880400
  [31:30] wifi_ax_submode_8, [29:28] wifi_dac_bias_8, [27:26] wifi_gc_tbb_boost_8, [25:21] wifi_gc_tbb_8, [20:18] wifi_gc_tmx_8, [17:11] wifi_dg1_qdb_8, [10:0] wifi_iqc_gain_8
0x750 pwr_wifi_tbl_17 reset 0x2080
  [31] wifi_dpd_en_ax_8, [30] wifi_dpd_en_n_8, [29] wifi_dpd_en_g_8, [28] wifi_dpd_en_b_8, [27] wifi_pa_lp_en_8, [26:24] wifi_gc_pa_8, [23:14] wifi_iqc_phase_8, [13:8] wifi_tosdac_i_8, [7:2] wifi_tosdac_q_8, [1:0] wifi_dpd_sel_8
0x754 pwr_wifi_tbl_18 reset 0x10880400
  [31:30] wifi_ax_submode_9, [29:28] wifi_dac_bias_9, [27:26] wifi_gc_tbb_boost_9, [25:21] wifi_gc_tbb_9, [20:18] wifi_gc_tmx_9, [17:11] wifi_dg1_qdb_9, [10:0] wifi_iqc_gain_9
0x758 pwr_wifi_tbl_19 reset 0x2080
  [31] wifi_dpd_en_ax_9, [30] wifi_dpd_en_n_9, [29] wifi_dpd_en_g_9, [28] wifi_dpd_en_b_9, [27] wifi_pa_lp_en_9, [26:24] wifi_gc_pa_9, [23:14] wifi_iqc_phase_9, [13:8] wifi_tosdac_i_9, [7:2] wifi_tosdac_q_9, [1:0] wifi_dpd_sel_9
0x75C pwr_wifi_tbl_20 reset 0x10880400
  [31:30] wifi_ax_submode_10, [29:28] wifi_dac_bias_10, [27:26] wifi_gc_tbb_boost_10, [25:21] wifi_gc_tbb_10, [20:18] wifi_gc_tmx_10, [17:11] wifi_dg1_qdb_10, [10:0] wifi_iqc_gain_10
0x760 pwr_wifi_tbl_21 reset 0x2080
  [31] wifi_dpd_en_ax_10, [30] wifi_dpd_en_n_10, [29] wifi_dpd_en_g_10, [28] wifi_dpd_en_b_10, [27] wifi_pa_lp_en_10, [26:24] wifi_gc_pa_10, [23:14] wifi_iqc_phase_10, [13:8] wifi_tosdac_i_10, [7:2] wifi_tosdac_q_10, [1:0] wifi_dpd_sel_10
0x764 pwr_wifi_tbl_22 reset 0x10880400
  [31:30] wifi_ax_submode_11, [29:28] wifi_dac_bias_11, [27:26] wifi_gc_tbb_boost_11, [25:21] wifi_gc_tbb_11, [20:18] wifi_gc_tmx_11, [17:11] wifi_dg1_qdb_11, [10:0] wifi_iqc_gain_11
0x768 pwr_wifi_tbl_23 reset 0x2080
  [31] wifi_dpd_en_ax_11, [30] wifi_dpd_en_n_11, [29] wifi_dpd_en_g_11, [28] wifi_dpd_en_b_11, [27] wifi_pa_lp_en_11, [26:24] wifi_gc_pa_11, [23:14] wifi_iqc_phase_11, [13:8] wifi_tosdac_i_11, [7:2] wifi_tosdac_q_11, [1:0] wifi_dpd_sel_11
0x76C pwr_wifi_tbl_24 reset 0x10880400
  [31:30] wifi_ax_submode_12, [29:28] wifi_dac_bias_12, [27:26] wifi_gc_tbb_boost_12, [25:21] wifi_gc_tbb_12, [20:18] wifi_gc_tmx_12, [17:11] wifi_dg1_qdb_12, [10:0] wifi_iqc_gain_12
0x770 pwr_wifi_tbl_25 reset 0x2080
  [31] wifi_dpd_en_ax_12, [30] wifi_dpd_en_n_12, [29] wifi_dpd_en_g_12, [28] wifi_dpd_en_b_12, [27] wifi_pa_lp_en_12, [26:24] wifi_gc_pa_12, [23:14] wifi_iqc_phase_12, [13:8] wifi_tosdac_i_12, [7:2] wifi_tosdac_q_12, [1:0] wifi_dpd_sel_12
0x774 pwr_bz_ctrl_0
  [4n+3:4n] bz_tx_backoff_{n:02} (n=0..7)
0x778 pwr_bz_ctrl_1
  [4n-29:4n-32] bz_tx_backoff_{n:02} (n=8..15)
0x77C pwr_bz_ctrl_2
  [4n-61:4n-64] bz_tx_backoff_{n} (n=16..20)
0x780 pwr_bz_ctrl_3
  [6n+5:6n] bz_tx_corr_{n} (n=0..4)
0x784 pwr_bz_ctrl_4
  [6n+5:6n] bz_tx_temp_{n} (n=0..4)
0x788 pwr_bz_ctrl_5 reset 0x18C498
  [6n+5:6n] bz_nominal_pwr_{n} (n=0..3)
0x78C pwr_bz_tbl_0 reset 0x10DC0400
  [29:28] bz_dac_bias_0, [27:26] bz_gc_tbb_boost_0, [25:21] bz_gc_tbb_0, [20:18] bz_gc_tmx_0, [17:11] bz_dg1_qdb_0, [10:0] bz_iqc_gain_0
0x790 pwr_bz_tbl_1 reset 0x2080
  [28] bz_dpd_en_0, [27] bz_pa_lp_en_0, [26:24] bz_gc_pa_0, [23:14] bz_iqc_phase_0, [13:8] bz_tosdac_i_0, [7:2] bz_tosdac_q_0, [1:0] bz_dpd_sel_0
0x794 pwr_bz_tbl_2 reset 0x109C0400
  [29:28] bz_dac_bias_1, [27:26] bz_gc_tbb_boost_1, [25:21] bz_gc_tbb_1, [20:18] bz_gc_tmx_1, [17:11] bz_dg1_qdb_1, [10:0] bz_iqc_gain_1
0x798 pwr_bz_tbl_3 reset 0x2080
  [28] bz_dpd_en_1, [27] bz_pa_lp_en_1, [26:24] bz_gc_pa_1, [23:14] bz_iqc_phase_1, [13:8] bz_tosdac_i_1, [7:2] bz_tosdac_q_1, [1:0] bz_dpd_sel_1
0x79C pwr_bz_tbl_4 reset 0x107C0400
  [29:28] bz_dac_bias_2, [27:26] bz_gc_tbb_boost_2, [25:21] bz_gc_tbb_2, [20:18] bz_gc_tmx_2, [17:11] bz_dg1_qdb_2, [10:0] bz_iqc_gain_2
0x7A0 pwr_bz_tbl_6 reset 0x2080
  [28] bz_dpd_en_2, [27] bz_pa_lp_en_2, [26:24] bz_gc_pa_2, [23:14] bz_iqc_phase_2, [13:8] bz_tosdac_i_2, [7:2] bz_tosdac_q_2, [1:0] bz_dpd_sel_2
0x7A4 pwr_bz_tbl_7 reset 0x105C0400
  [29:28] bz_dac_bias_3, [27:26] bz_gc_tbb_boost_3, [25:21] bz_gc_tbb_3, [20:18] bz_gc_tmx_3, [17:11] bz_dg1_qdb_3, [10:0] bz_iqc_gain_3
0x7A8 pwr_bz_tbl_8 reset 0x2080
  [28] bz_dpd_en_3, [27] bz_pa_lp_en_3, [26:24] bz_gc_pa_3, [23:14] bz_iqc_phase_3, [13:8] bz_tosdac_i_3, [7:2] bz_tosdac_q_3, [1:0] bz_dpd_sel_3
0x7AC pwr_ctrl_0 (reset mask 0x800000FF)
  [31] rf_tx_reduce_pwr_ena, [27:8] rf_tx_pwr_sts ro, [7:0] wifi_tx_corr_dsss
0x7B0 pwr_ctrl_1 reset 0x4030201
  [31:24] rf_tx_reduce_pwr_ble, [23:16] rf_tx_reduce_pwr_zb, [15:8] rf_tx_reduce_pwr_bt, [7:0] rf_tx_reduce_pwr_wifi
0x7B4 pwr_ctrl_3
  [6n+5:6n] bt_tx_corr_{n} (n=0..4)
0x7B8 pwr_ctrl_4
  [6n+5:6n] bt_tx_temp_{n} (n=0..4)
0x7BC pa_config_b reset 0x1610E4
  [21] wifi_pa_ib_fix_b, [20] wifi_pa_etb_en_b, [19:16] wifi_pa_vbcore_b, [15:12] wifi_pa_vbpmos_b, [11:10] wifi_pa_vbpmos_iet_b, [9:6] wifi_pa_iet_b, [5:3] wifi_pa_iaq_b, [2:0] wifi_pa_vbcas_b
0x7C0 pa_config_g reset 0x1610E4
  [21] wifi_pa_ib_fix_g, [20] wifi_pa_etb_en_g, [19:16] wifi_pa_vbcore_g, [15:12] wifi_pa_vbpmos_g, [11:10] wifi_pa_vbpmos_iet_g, [9:6] wifi_pa_iet_g, [5:3] wifi_pa_iaq_g, [2:0] wifi_pa_vbcas_g
0x7C4 pa_config_n reset 0x1610E4
  [21] wifi_pa_ib_fix_n, [20] wifi_pa_etb_en_n, [19:16] wifi_pa_vbcore_n, [15:12] wifi_pa_vbpmos_n, [11:10] wifi_pa_vbpmos_iet_n, [9:6] wifi_pa_iet_n, [5:3] wifi_pa_iaq_n, [2:0] wifi_pa_vbcas_n
0x7C8 pa_config_ax_sub_mode0 reset 0x1610E4
  [21] wifi_pa_ib_fix_ax0, [20] wifi_pa_etb_en_ax0, [19:16] wifi_pa_vbcore_ax0, [15:12] wifi_pa_vbpmos_ax0, [11:10] wifi_pa_vbpmos_iet_ax0, [9:6] wifi_pa_iet_ax0, [5:3] wifi_pa_iaq_ax0, [2:0] wifi_pa_vbcas_ax0
0x7CC pa_config_ax_sub_mode1 reset 0x1A08E4
  [21] wifi_pa_ib_fix_ax1, [20] wifi_pa_etb_en_ax1, [19:16] wifi_pa_vbcore_ax1, [15:12] wifi_pa_vbpmos_ax1, [11:10] wifi_pa_vbpmos_iet_ax1, [9:6] wifi_pa_iet_ax1, [5:3] wifi_pa_iaq_ax1, [2:0] wifi_pa_vbcas_ax1
0x7D0 pa_config_ax_sub_mode2 reset 0x1A0CE4
  [21] wifi_pa_ib_fix_ax2, [20] wifi_pa_etb_en_ax2, [19:16] wifi_pa_vbcore_ax2, [15:12] wifi_pa_vbpmos_ax2, [11:10] wifi_pa_vbpmos_iet_ax2, [9:6] wifi_pa_iet_ax2, [5:3] wifi_pa_iaq_ax2, [2:0] wifi_pa_vbcas_ax2
0x7D4 pa_config_ax_sub_mode3 reset 0x160CE4
  [21] wifi_pa_ib_fix_ax3, [20] wifi_pa_etb_en_ax3, [19:16] wifi_pa_vbcore_ax3, [15:12] wifi_pa_vbpmos_ax3, [11:10] wifi_pa_vbpmos_iet_ax3, [9:6] wifi_pa_iet_ax3, [5:3] wifi_pa_iaq_ax3, [2:0] wifi_pa_vbcas_ax3
0x7D8 pa_config_bz reset 0x2510E4
  [21] bz_pa_ib_fix, [20] bz_pa_etb_en, [19:16] bz_pa_vbcore, [15:12] bz_pa_vbpmos, [11:10] bz_pa_vbpmos_iet, [9:6] bz_pa_iet, [5:3] bz_pa_iaq, [2:0] bz_pa_vbcas
0x7DC tx_dpd_sram_ctrl_0
  [29] tx_dpd_pha_manu_read_en, [28] tx_dpd_amp_manu_read_en, [27:20] tx_dpd_pha_manu_read_addr, [19:12] tx_dpd_amp_manu_read_addr, [2:0] tx_dpd_page_num
0x7E0 tx_dpd_sram_ctrl_1 reset not defined
  [23:0] tx_dpd_amp_spram_rddata ro
0x7E4 tx_dpd_sram_ctrl_2 reset not defined
  [27:0] tx_dpd_pha_spram_rddata ro
0x800 tx_dpd_ctrl_0 reset 0x690000
  [22:21] tx_dpd_comp_mode, [20:15] tx_dpd_lp_th, [14] tx_dpd_lp_ctrl_on, [13] tx_dpd_ctrl_hw, [12] tx_dpd_lut_mode, [11] tx_dpd_lut_x_mode, [10] tx_dpd_lut_p_mode, [9] tx_dpd_in_scal_en, [8:3] tx_dpd_in_scal, [2] tx_dpd_pmon, [1] tx_dpd_amon, [0] tx_dpd_en
0x804 tx_dpd_ctrl_1
  [11:8] tx_dpd_en_dsss, [7:0] tx_dpd_en_ofdm
0xA10 rx_dpd_ctrl_0 reset 0x6201000 (reset mask 0x8FFFFFFE)
  [31] sram_clk_4s_en
  [27] rx_dpd_sw_reset
  [26] rx_dpd_sram_en — 1:enable DPD sram
  [25] rx_dpd_sel — 0:CPU, 1:DPD
  [24] rx_dpd_en — 1:enable DPD engine
  [23:21] rx_dpd_n_period
  [20:18] rx_dpd_dgc_shift
  [17:13] rx_dpd_dgc_gain_dB
  [12:8] rx_dpd_fc_mhz
  [7:3] rx_dpd_wait_time_us
  [2] rx_dpd_bypass_filter
  [1] rx_dpd_i_path_only
  [0] rx_dpd_done ro
0xA14 rx_dpd_ctrl_1 reset 0x71000
  [25:16] rx_dpd_dly_th, [12] rx_dpd_use_sync_mf, [11:10] rx_dpd_sync_mf_in_mag_th, [9:8] rx_dpd_sync_mf_out_mag_th, [7:0] rx_dpd_sample_offset
